AUTOSAR XML (schema 4-3-0)
package /BswM_Component_ARPkg
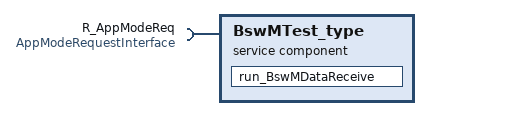
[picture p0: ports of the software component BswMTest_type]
  service sw component type BswMTest_type
    require port R_AppModeReq: nonqueued-receiver-com-spec{data-element=requestedMode, init-value=APP_MODE_ACTIVE}, required-interface=AppModeRequestInterface
    behavior BswMTest_type_IB: data-type-mapping=AppModeTypeMap, handle-termination-and-restart=NO-SUPPORT, included-mode-declaration-group-set{mode-declaration-group=AppModeGroup, prefix=IncludeAppModeType}
      data received event DRE_BswMAppModeReq: start-on-event=run_BswMDataReceive, data=R_AppModeReq.requestedMode
      runnable run_BswMDataReceive
        data-receive-point-by-arguments:
          access drparg_requestedMode: accessed-variable=R_AppModeReq.requestedMode
package /Impl_BswMTest_ARPkg
  swc implementation Impl_BswMTest_type: programming-language=C, sw-version=1.0.0, vendor-id=0, behavior=BswMTest_type_IB
    code-descriptors:
      code SRC: artifact-descriptors=autosar-engineering-object={short-label=EngObject, category=SWSRC}
    resource consumption ResourceConsumption
      memory section MEM_BswM_type: size=0, sw-addrmethod=CODE, symbol=CODE
